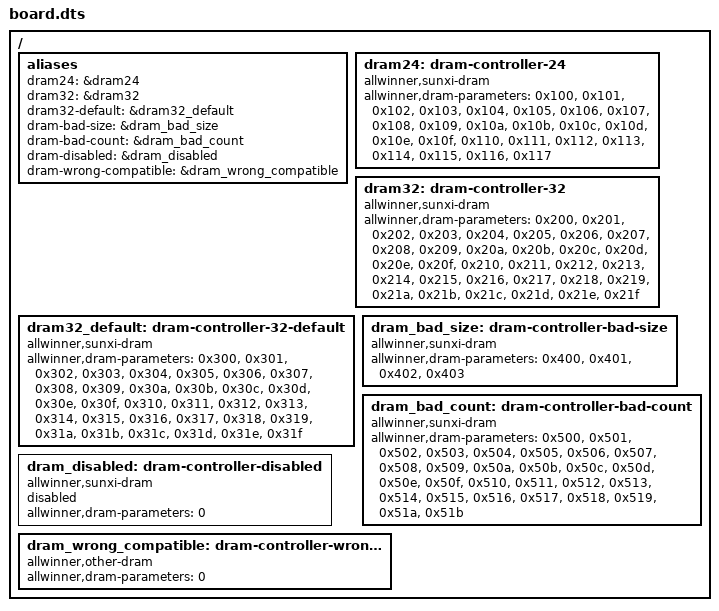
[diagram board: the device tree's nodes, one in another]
/dts-v1/;

/ {
	aliases {
		dram24 = &dram24;
		dram32 = &dram32;
		dram32-default = &dram32_default;
		dram-bad-size = &dram_bad_size;
		dram-bad-count = &dram_bad_count;
		dram-disabled = &dram_disabled;
		dram-wrong-compatible = &dram_wrong_compatible;
	};

	dram24: dram-controller-24 {
		compatible = "allwinner,sunxi-dram";
		allwinner,dram-parameters =
			<0x100>, <0x101>, <0x102>, <0x103>,
			<0x104>, <0x105>, <0x106>, <0x107>,
			<0x108>, <0x109>, <0x10a>, <0x10b>,
			<0x10c>, <0x10d>, <0x10e>, <0x10f>,
			<0x110>, <0x111>, <0x112>, <0x113>,
			<0x114>, <0x115>, <0x116>, <0x117>;
		status = "okay";
	};

	dram32: dram-controller-32 {
		compatible = "allwinner,sunxi-dram";
		allwinner,dram-parameters =
			<0x200>, <0x201>, <0x202>, <0x203>,
			<0x204>, <0x205>, <0x206>, <0x207>,
			<0x208>, <0x209>, <0x20a>, <0x20b>,
			<0x20c>, <0x20d>, <0x20e>, <0x20f>,
			<0x210>, <0x211>, <0x212>, <0x213>,
			<0x214>, <0x215>, <0x216>, <0x217>,
			<0x218>, <0x219>, <0x21a>, <0x21b>,
			<0x21c>, <0x21d>, <0x21e>, <0x21f>;
		status = "okay";
	};

	dram32_default: dram-controller-32-default {
		compatible = "allwinner,sunxi-dram";
		allwinner,dram-parameters =
			<0x300>, <0x301>, <0x302>, <0x303>,
			<0x304>, <0x305>, <0x306>, <0x307>,
			<0x308>, <0x309>, <0x30a>, <0x30b>,
			<0x30c>, <0x30d>, <0x30e>, <0x30f>,
			<0x310>, <0x311>, <0x312>, <0x313>,
			<0x314>, <0x315>, <0x316>, <0x317>,
			<0x318>, <0x319>, <0x31a>, <0x31b>,
			<0x31c>, <0x31d>, <0x31e>, <0x31f>;
		status = "okay";
	};

	dram_bad_size: dram-controller-bad-size {
		compatible = "allwinner,sunxi-dram";
		allwinner,dram-parameters = <0x400>, <0x401>, <0x402>, <0x403>;
		status = "okay";
	};

	dram_bad_count: dram-controller-bad-count {
		compatible = "allwinner,sunxi-dram";
		allwinner,dram-parameters =
			<0x500>, <0x501>, <0x502>, <0x503>,
			<0x504>, <0x505>, <0x506>, <0x507>,
			<0x508>, <0x509>, <0x50a>, <0x50b>,
			<0x50c>, <0x50d>, <0x50e>, <0x50f>,
			<0x510>, <0x511>, <0x512>, <0x513>,
			<0x514>, <0x515>, <0x516>, <0x517>,
			<0x518>, <0x519>, <0x51a>, <0x51b>;
		status = "okay";
	};

	dram_disabled: dram-controller-disabled {
		compatible = "allwinner,sunxi-dram";
		allwinner,dram-parameters = <0>;
		status = "disabled";
	};

	dram_wrong_compatible: dram-controller-wrong-compatible {
		compatible = "allwinner,other-dram";
		allwinner,dram-parameters = <0>;
		status = "okay";
	};
};
